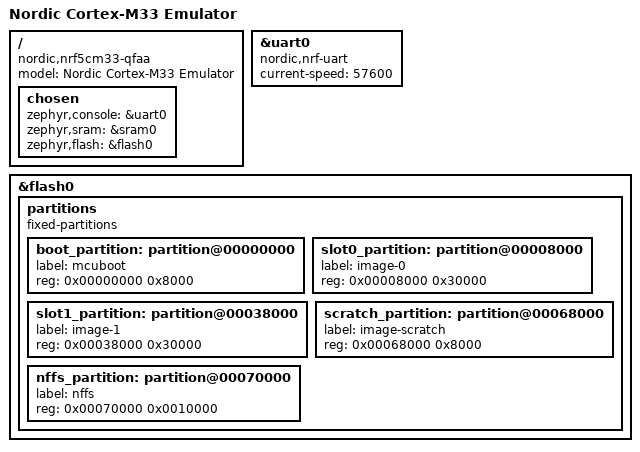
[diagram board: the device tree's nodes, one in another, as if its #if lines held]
/*
 * Copyright (c) 2018 Ioannis Glaropoulos <Ioannis.Glaropoulos@nordicsemi.no>
 *
 * SPDX-License-Identifier: Apache-2.0
 */

/dts-v1/;
#include <nordic/nrf5cm33.dtsi>

/ {
	model = "Nordic Cortex-M33 Emulator";
	compatible = "nordic,nrf5cm33-qfaa",
		     "nordic,nrf5cm33";

	chosen {
		zephyr,console = &uart0;
		zephyr,sram = &sram0;
		zephyr,flash = &flash0;
	};
};

&uart0 {
	status = "ok";
	compatible = "nordic,nrf-uart";
	current-speed = <57600>;
};

&flash0 {
	/*
	 * If chosen's zephyr,code-partition
	 * is unset, the image will be linked
	 * into the entire flash device.  If
	 * it points to an individual
	 * partition, the code will be linked
	 * to, and restricted to that
	 * partition.
	 */
	partitions {
		compatible = "fixed-partitions";
		#address-cells = <1>;
		#size-cells = <1>;

		boot_partition: partition@00000000 {
			label = "mcuboot";
			reg = <0x00000000 0x8000>;
		};
		slot0_partition: partition@00008000 {
			label = "image-0";
			reg = <0x00008000 0x30000>;
		};
		slot1_partition: partition@00038000 {
			label = "image-1";
			reg = <0x00038000 0x30000>;
		};
		scratch_partition: partition@00068000 {
			label = "image-scratch";
			reg = <0x00068000 0x8000>;
		};

		/*
		 * The flash starting at 0x00070000 and ending at
		 * 0x0007ffff (sectors 125-127) is reserved for use
		 * by the application. If enabled, partition for NFFS
		 * will be created in this area.
		 */

#if defined(CONFIG_FILE_SYSTEM_NFFS)
		nffs_partition: partition@00070000 {
			label = "nffs";
			reg = <0x00070000 0x0010000>;
		};
#endif
	};
};
